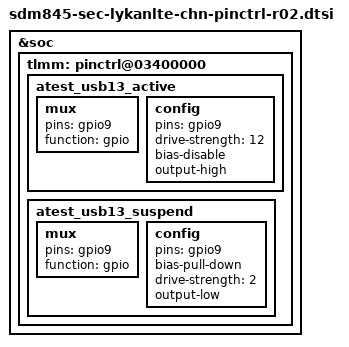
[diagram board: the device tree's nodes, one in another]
/* Copyright (c) 2016-2017, The Linux Foundation. All rights reserved.
 *
 * This program is free software; you can redistribute it and/or modify
 * it under the terms of the GNU General Public License version 2 and
 * only version 2 as published by the Free Software Foundation.
 *
 * This program is distributed in the hope that it will be useful,
 * but WITHOUT ANY WARRANTY; without even the implied warranty of
 * MERCHANTABILITY or FITNESS FOR A PARTICULAR PURPOSE.  See the
 * GNU General Public License for more details.
 */

#include "sdm845-sec-lykanlte-chn-pinctrl-r01.dtsi"

&soc {
	tlmm: pinctrl@03400000 {

		atest_usb13_active: atest_usb13_active {
			mux {
				pins = "gpio9";
				function = "gpio";
			};
			config {
				pins = "gpio9";
				drive-strength = <12>;
				bias-disable;
				output-high;
			};
		};

		atest_usb13_suspend: atest_usb13_suspend {
			mux {
				pins = "gpio9";
				function = "gpio";
			};
			config {
				pins = "gpio9";
				bias-pull-down;
				drive-strength = <2>;
				output-low;
			};
		};
	};
};
